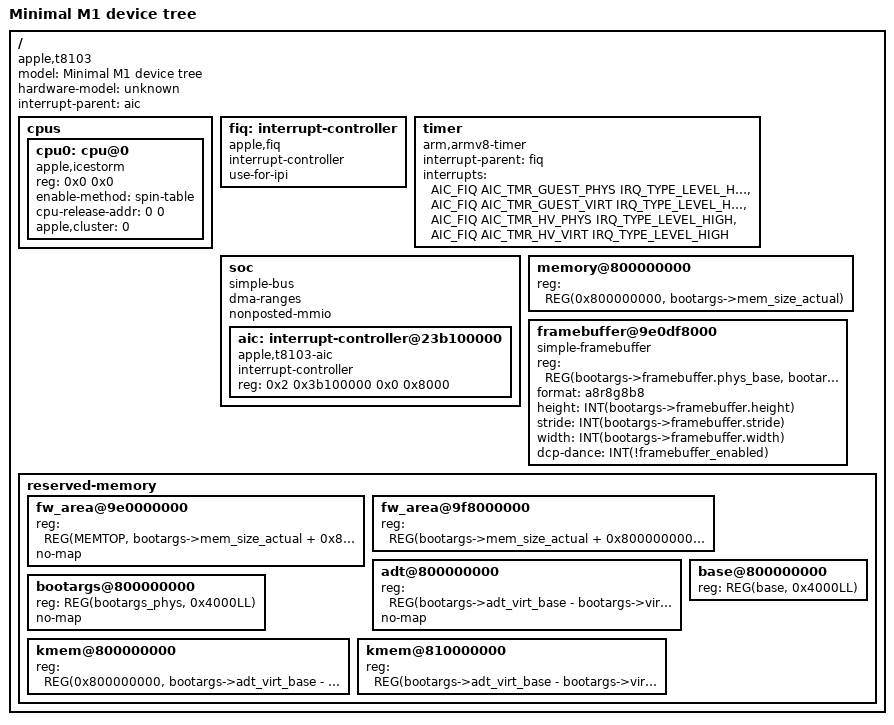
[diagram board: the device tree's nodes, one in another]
#define SZ_1G (1LL << 30)
#define MEMTOP (0x800000000 + (bootargs->mem_size))

#define AIC_FIQ 1
#define AIC_TMR_HV_PHYS		0
#define AIC_TMR_HV_VIRT		1
#define AIC_TMR_GUEST_PHYS	2
#define AIC_TMR_GUEST_VIRT	3
#define IRQ_TYPE_NONE		0
#define IRQ_TYPE_EDGE_RISING	1
#define IRQ_TYPE_EDGE_FALLING	2
#define IRQ_TYPE_EDGE_BOTH	(IRQ_TYPE_EDGE_FALLING | IRQ_TYPE_EDGE_RISING)
#define IRQ_TYPE_LEVEL_HIGH	4
#define SZ_1G (1LL << 30)
#define REG(x,y) <${cpu_to_be32(((u64)(x))>>32)} \
	          ${cpu_to_be32(((u64)(x))&U32_MAX)} \
		  ${cpu_to_be32(((u64)(y))>>32)} \
		  ${cpu_to_be32(((u64)(y))&U32_MAX)}>

#define INT(x) <${cpu_to_be32(x)}>

/dts-v1/;

/ {
	model = "Minimal M1 device tree";
	compatible = "apple,t8103", "apple,arm-platform";
	hardware-model = "unknown";
	interrupt-parent = <&aic>;
	#address-cells = <2>;
	#size-cells = <2>;


	cpus {
		#address-cells = <2>;
		#size-cells = <0>;

		cpu0: cpu@0 {
			compatible = "apple,icestorm";
			device_type = "cpu";
			reg = <0x0 0x0>;
			enable-method = "spin-table";
			cpu-release-addr = <0 0>; /* To be filled by loader */
			apple,cluster = <0>;
		};
	};

	fiq: interrupt-controller {
	        compatible = "apple,fiq";
		#interrupt-cells = <3>;
		interrupt-controller;
		use-for-ipi;
	};

	timer {
		compatible = "arm,armv8-timer";
		interrupt-parent = <&fiq>;
		interrupt-names = "phys", "virt", "hyp-phys", "hyp-virt";
		interrupts = <AIC_FIQ AIC_TMR_GUEST_PHYS IRQ_TYPE_LEVEL_HIGH>,
			     <AIC_FIQ AIC_TMR_GUEST_VIRT IRQ_TYPE_LEVEL_HIGH>,
			     <AIC_FIQ AIC_TMR_HV_PHYS IRQ_TYPE_LEVEL_HIGH>,
			     <AIC_FIQ AIC_TMR_HV_VIRT IRQ_TYPE_LEVEL_HIGH>;
	};

	soc {
		compatible = "simple-bus";
		#address-cells = <2>;
		#size-cells = <2>;

		ranges;
		dma-ranges;
		nonposted-mmio;

		/* You might think the minimal kernel does not require
		 * an interrupt controller, and you'd be right: in ARM
		 * terminology, the minimal kernel uses only FIQs, no
		 * IRQs. However, FIQ handling is currently done in the
		 * AIC driver; it shouldn't be, and this shouldn't be
		 * here. */

		aic: interrupt-controller@23b100000 {
			compatible = "apple,t8103-aic", "apple,aic";
			#interrupt-cells = <3>;
			interrupt-controller;
			reg = <0x2 0x3b100000 0x0 0x8000>;
		};
	};

	memory@800000000 {
		device_type = "memory";
		reg = REG(0x800000000, bootargs->mem_size_actual);
	};

	framebuffer@9e0df8000 {
		#address-cells = <0x02>;
		#size-cells = <0x02>;
		compatible = "simple-framebuffer";
		reg = REG(bootargs->framebuffer.phys_base,
		          bootargs->framebuffer.stride *
			  bootargs->framebuffer.height);
		format = "a8r8g8b8";
		height = INT(bootargs->framebuffer.height);
		stride = INT(bootargs->framebuffer.stride);
		width = INT(bootargs->framebuffer.width);
		status = "okay";
		dcp-dance = INT(!framebuffer_enabled);
	};

	/* Technically, these areas shouldn't overlap. */
	reserved-memory {
		#address-cells = <0x02>;
		#size-cells = <0x02>;
		ranges;

		/* The area at the end of memory. Not actually at 9e0000000. */
		fw_area@9e0000000 {
		        reg = REG(MEMTOP,
			          bootargs->mem_size_actual + 0x800000000
				   - 0x100000 - MEMTOP);
			no-map;
		};

		fw_area@9f8000000 {
			reg = REG(bootargs->mem_size_actual + 0x800000000
				      -	0x100000,
				      0x100000LL);
		};

		/* The Apple Device tree. */
		adt@800000000 {
			reg = REG(bootargs->adt_virt_base
			          - bootargs->virt_base
				  + bootargs->phys_base,
				  (u64)bootargs->adt_size);
			no-map;
		};

		/* The bootargs structure. */
		bootargs@800000000 {
			reg = REG(bootargs_phys, 0x4000LL);
			no-map;
		};

		/* Other memory below the start of usable memory, currently
		 * including the original kernel .macho. */
		kmem@800000000 {
			reg = REG(0x800000000,
			          bootargs->adt_virt_base
				  - bootargs->virt_base
				  + bootargs->phys_base
				  - 0x800000000);
		};
		kmem@810000000 {
			reg = REG(bootargs->adt_virt_base
				  - bootargs->virt_base
				  + bootargs->phys_base
				  + (u64)bootargs->adt_size,
			          bootargs_phys
				  - (bootargs->adt_virt_base
				     - bootargs->virt_base
				     + bootargs->phys_base
				     + (u64)bootargs->adt_size));
		};

		base@800000000 {
			reg = REG(base, 0x4000LL);
		};

	};
};
